# EFM32G880F128 register map
File version: 5.2.1
Registers are 32-bit, read-write, reset 0x0 unless marked. A register's access mark holds for its fields unless they carry their own. Offsets are from the block's base; [hi:lo] are bit positions; {n}, {i} and the like mark numbered series.

## EMU
Base 0x400C6000
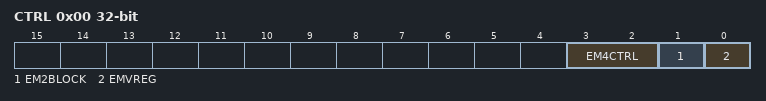
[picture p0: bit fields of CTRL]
0x00 CTRL — Control Register
  [3:2] EM4CTRL — Energy Mode 4 Control
  [1] EM2BLOCK — Energy Mode 2 Block
  [0] EMVREG — Energy Mode Voltage Regulator Control
0x04 MEMCTRL — Memory Control Register
  [2:0] POWERDOWN — RAM block power-down
    4=BLK3 (Power down RAM block 3 (address range 0x20018000-0x2001FFFF).); 6=BLK23 (Power down RAM blocks 2-3 (address range 0x20010000-0x2001FFFF).); 7=BLK123 (Power down RAM blocks 1-3 (address range 0x20008000-0x2001FFFF).)
0x08 LOCK — Configuration Lock Register
  [15:0] LOCKKEY — Configuration Lock Key
    0=UNLOCKED; 1=LOCKED
0x24 AUXCTRL — Auxiliary Control Register
  [0] HRCCLR — Hard Reset Cause Clear

## RMU
Base 0x400CA000
0x00 CTRL — Control Register
  [0] LOCKUPRDIS — Lockup Reset Disable
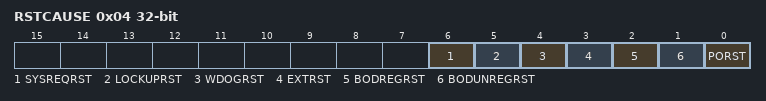
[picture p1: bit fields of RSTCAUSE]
0x04 RSTCAUSE ro — Reset Cause Register
  [6] SYSREQRST — System Request Reset
  [5] LOCKUPRST — LOCKUP Reset
  [4] WDOGRST — Watchdog Reset
  [3] EXTRST — External Pin Reset
  [2] BODREGRST — Brown Out Detector Regulated Domain Reset
  [1] BODUNREGRST — Brown Out Detector Unregulated Domain Reset
  [0] PORST — Power On Reset
0x08 CMD wo — Command Register
  [0] RCCLR — Reset Cause Clear

## EBI
Base 0x40008000
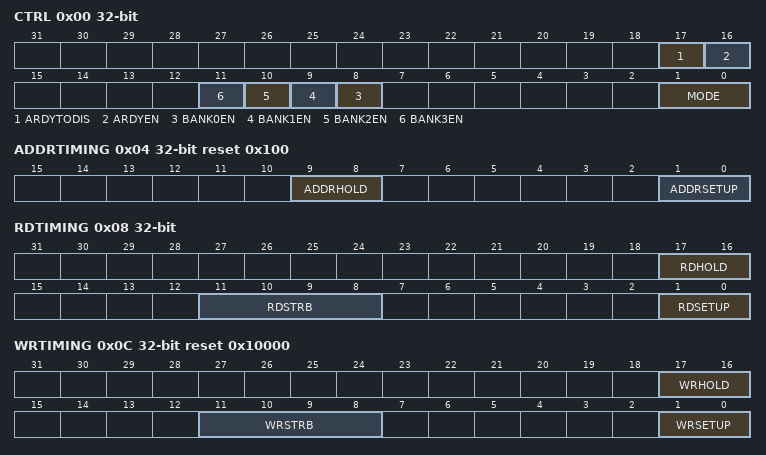
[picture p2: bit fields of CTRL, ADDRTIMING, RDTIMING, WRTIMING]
0x00 CTRL — Control Register
  [17] ARDYTODIS — ARDY Timeout Disable
  [16] ARDYEN — ARDY Enable
  [n+8] BANK{n}EN (n=0..3) — Bank {n} Enable
  [1:0] MODE
    0=D8A8 (8 bit data, 8 bit address, ALE not used.); 1=D16A16ALE (16 bit data, 16 bit address, ALE is used for address latching.); 2=D8A24ALE (8 bit data, 24 bit address, ALE is used for address latching.)
0x04 ADDRTIMING reset 0x100 — Address Timing Register
  [9:8] ADDRHOLD — Address Hold Time
  [1:0] ADDRSETUP — Address Setup Time
0x08 RDTIMING — Read Timing Register
  [17:16] RDHOLD — Read Hold Time
  [11:8] RDSTRB — Read Strobe Time
  [1:0] RDSETUP — Read Setup Time
0x0C WRTIMING reset 0x10000 — Write Timing Register
  [17:16] WRHOLD — Write Hold Time
  [11:8] WRSTRB — Write Strobe Time
  [1:0] WRSETUP — Write Setup Time
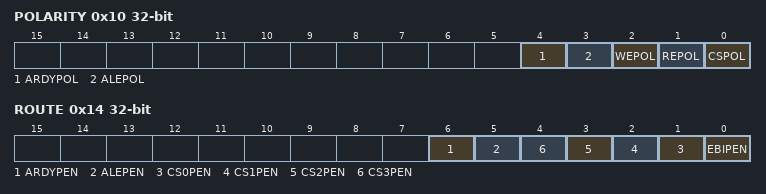
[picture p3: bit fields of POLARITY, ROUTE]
0x10 POLARITY
  [4] ARDYPOL — ARDY Polarity
  [3] ALEPOL — Address Latch Polarity
  [2] WEPOL — Write Enable Polarity
  [1] REPOL — Read Enable Polarity
  [0] CSPOL — Chip Select Polarity
0x14 ROUTE — I/O Routing Register
  [6] ARDYPEN — EBI_ARDY Pin Enable
  [5] ALEPEN — EBI_ALE Pin Enable
  [n+1] CS{n}PEN (n=0..3) — EBI_CS{n} Pin Enable
  [0] EBIPEN — EBI Pin Enable

## RTC
Base 0x40080000
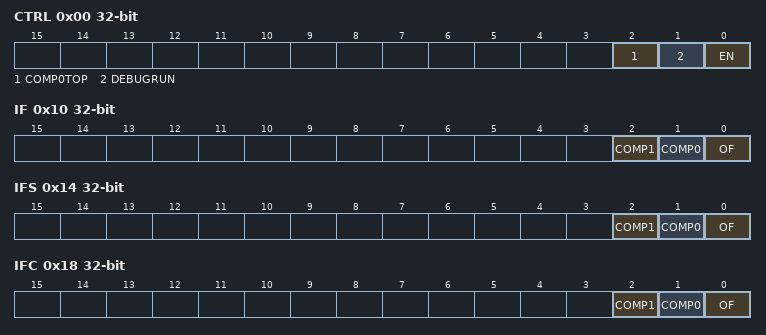
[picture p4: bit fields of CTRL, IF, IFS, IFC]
0x00 CTRL — Control Register
  [2] COMP0TOP — Compare Channel 0 is Top Value
  [1] DEBUGRUN — Debug Mode Run Enable
  [0] EN — RTC Enable
0x04 CNT ro — Counter Value Register
  [23:0] CNT — Counter Value
0x08 COMP0 — Compare Value Register 0
  [23:0] COMP0 — Compare Value 0
0x0C COMP1 — Compare Value Register 1
  [23:0] COMP1 — Compare Value 1
0x10 IF ro — Interrupt Flag Register
  [2] COMP1 — Compare Match 1 Interrupt Flag
  [1] COMP0 — Compare Match 0 Interrupt Flag
  [0] OF — Overflow Interrupt Flag
0x14 IFS wo — Interrupt Flag Set Register
  [2] COMP1 — Set Compare match 1 Interrupt Flag
  [1] COMP0 — Set Compare match 0 Interrupt Flag
  [0] OF — Set Overflow Interrupt Flag
0x18 IFC wo — Interrupt Flag Clear Register
  [2] COMP1 — Clear Compare match 1 Interrupt Flag
  [1] COMP0 — Clear Compare match 0 Interrupt Flag
  [0] OF — Clear Overflow Interrupt Flag
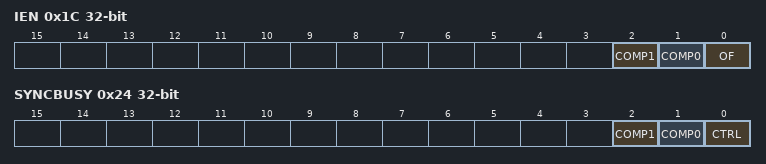
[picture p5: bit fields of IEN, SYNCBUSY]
0x1C IEN — Interrupt Enable Register
  [2] COMP1 — Compare Match 1 Interrupt Enable
  [1] COMP0 — Compare Match 0 Interrupt Enable
  [0] OF — Overflow Interrupt Enable
0x20 FREEZE
  [0] REGFREEZE — Register Update Freeze
0x24 SYNCBUSY ro — Synchronization Busy Register
  [2] COMP1 — COMP1 Register Busy
  [1] COMP0 — COMP0 Register Busy
  [0] CTRL — CTRL Register Busy

## PCNT0
Base 0x40086000
Same registers: PCNT1 0x40086400, PCNT2 0x40086800
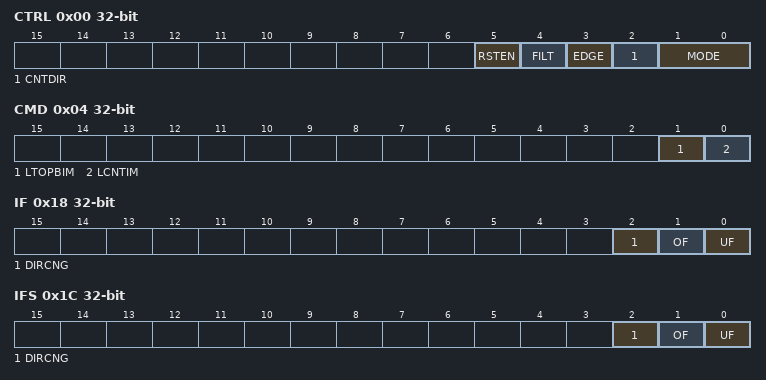
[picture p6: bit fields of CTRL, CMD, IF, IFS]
0x00 CTRL — Control Register
  [5] RSTEN — Enable PCNT Clock Domain Reset
  [4] FILT — Enable Digital Pulse Width Filter
  [3] EDGE — Edge Select
  [2] CNTDIR — Non-Quadrature Mode Counter Direction Control
  [1:0] MODE — Mode Select
    0=DISABLE (The module is disabled.); 1=OVSSINGLE (Single input LFACLK oversampling mode (available in EM0-EM2).); 2=EXTCLKSINGLE (Externally clocked single input counter mode (available in EM0-EM3).); 3=EXTCLKQUAD (Externally clocked quadrature decoder mode (available in EM0-EM3).)
0x04 CMD wo — Command Register
  [1] LTOPBIM — Load TOPB Immediately
  [0] LCNTIM — Load CNT Immediately
0x08 STATUS ro
  [0] DIR — Current Counter Direction
0x0C CNT ro — Counter Value Register
  [15:0] CNT — Counter Value
0x10 TOP ro reset 0xFF — Top Value Register
  [15:0] TOP — Counter Top Value
0x14 TOPB reset 0xFF — Top Value Buffer Register
  [15:0] TOPB — Counter Top Buffer
0x18 IF ro — Interrupt Flag Register
  [2] DIRCNG — Direction Change Detect Interrupt Flag
  [1] OF — Overflow Interrupt Read Flag
  [0] UF — Underflow Interrupt Read Flag
0x1C IFS wo — Interrupt Flag Set Register
  [2] DIRCNG — Direction Change Detect Interrupt Set
  [1] OF — Overflow Interrupt Set
  [0] UF — Underflow interrupt set
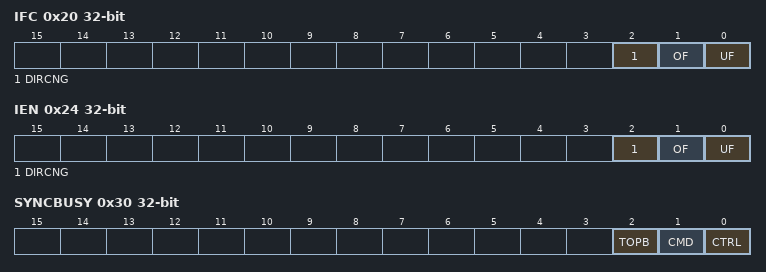
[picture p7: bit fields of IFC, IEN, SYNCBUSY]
0x20 IFC wo — Interrupt Flag Clear Register
  [2] DIRCNG — Direction Change Detect Interrupt Clear
  [1] OF — Overflow Interrupt Clear
  [0] UF — Underflow Interrupt Clear
0x24 IEN — Interrupt Enable Register
  [2] DIRCNG — Direction Change Detect Interrupt Enable
  [1] OF — Overflow Interrupt Enable
  [0] UF — Underflow Interrupt Enable
0x28 ROUTE — I/O Routing Register
  [9:8] LOCATION — I/O Location
    0=LOC0 (Location 0); 1=LOC1 (Location 1); 2=LOC2 (Location 2)
0x2C FREEZE
  [0] REGFREEZE — Register Update Freeze
0x30 SYNCBUSY ro — Synchronization Busy Register
  [2] TOPB — TOPB Register Busy
  [1] CMD — CMD Register Busy
  [0] CTRL — CTRL Register Busy
